# AC7840x register map
Vendor: AutoChips; Series: AC78; File version: 1.0
CPU: CM4 r0p1, little endian, MPU, FPU, VTOR, 4 interrupt priority bits
Registers are 32-bit, read-write, reset 0x0 unless marked. A register's access mark holds for its fields unless they carry their own. Offsets are from the block's base; [hi:lo] are bit positions; {n}, {i} and the like mark numbered series.

## SPI0 — Serial Peripheral Interface
Base 0x4000C000
Same registers: SPI1 0x4000C800, SPI2 0x4000D000
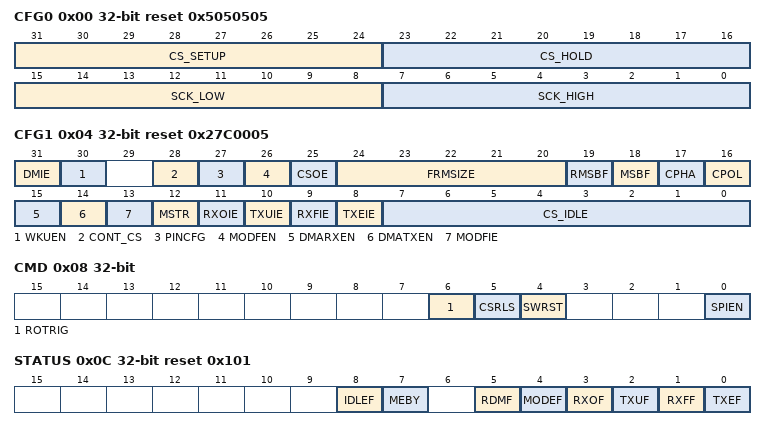
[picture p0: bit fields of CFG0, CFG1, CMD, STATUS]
0x00 CFG0 reset 0x5050505 — SPI Configuration Register 0
  [31:24] CS_SETUP — CS Setup Count
  [23:16] CS_HOLD — CS hold count
  [15:8] SCK_LOW — SCK low count
  [7:0] SCK_HIGH — SCK High Count
0x04 CFG1 reset 0x27C0005 — SPI Configuration Register 1
  [31] DMIE — Data match interrupt enable
    0=Disable; 1=Enable
  [30] WKUEN — wake up function enable(only valid for slave mode)
    0=Disable; 1=Enable
  [28] CONT_CS — CS continuous output enable
    0=Disable; 1=Enable
  [27] PINCFG — SOUT, SIN pin mode configuration
    0=SPI_SOUT_MOSI_SIN_MISO; 1=SPI_SOUT_MISO_SIN_MOSI
  [26] MODFEN — mode fault detect enable
    0=Disable; 1=Enable
  [25] CSOE — CS hardware output enable
    0=Disable; 1=Enable
  [24:20] FRMSIZE — frame size
    {v}=Frame size is 4 bits (v=0..3); {v}=Frame size is {v+1} bits (v=4..31)
  [19] RMSBF — RX MSB first Select
    0=RX LSB first; 1=RX MSB first
  [18] MSBF — TX MSB first Select
    0=TX LSB first; 1=TX MSB first
  [17] CPHA — clock phase
    0=the second SCK transition is the first data capture edge; 1=the first SCK transition is the first data capture edge
  [16] CPOL — clock polarity
    0=SCK is 0 when idle; 1=SCK is 1 when idle
  [15] DMARXEN — DMA RX channel enable
    0=Disable; 1=Enable
  [14] DMATXEN — DMA TX channel enable
    0=Disable; 1=Enable
  [13] MODFIE — mode fault interrupt enable
    0=Disable; 1=Enable
  [12] MSTR — master/slave mode selection
    0=SLAVE (SPI slave mode); 1=MASTER (SPI master mode)
  [11] RXOIE — RX buffer overflow interrupt enable
    0=Disable; 1=Enable
  [10] TXUIE — TX buffer underflow interrupt enable
    0=Disable; 1=Enable
  [9] RXFIE — RX buffer full interrupt enable
    0=Disable; 1=Enable
  [8] TXEIE — TX buffer empty interrupt enable
    0=Disable; 1=Enable
  [7:0] CS_IDLE — CS idle time
0x08 CMD — SPI Command Register
  [6] ROTRIG — Master RX only mode trigger
    0=No effect; 1=Trigger read
  [5] CSRLS — CS release(only valid for CS continuous output)
    0=No effect; 1=Release CS
  [4] SWRST — software reset
    0=No effect; 1=Reset
  [0] SPIEN — SPI Enable
    0=Disable; 1=Enable
0x0C STATUS reset 0x101 — SPI Status Register
  [8] IDLEF — SPI module hardware idle flag
    0=Not idle; 1=Idle
  [7] MEBY — SPI master engine busy flag
    0=Transmission finished; 1=Transmission not finish
  [5] RDMF — Receive data match flag
    0=No RX data match; 1=RX data match
  [4] MODEF — Mode error flag
    0=No mode fault; 1=Mode fault
  [3] RXOF — RX buffer overflow flag
    0=No RX overflow; 1=RX overflow
  [2] TXUF — TX buffer underflow flag
    0=No TX underflow; 1=TX underflow
  [1] RXFF — RX buffer Full flag
    0=RX not full; 1=RX full
  [0] TXEF — TX buffer empty flag
    0=TX Not empty; 1=TX empty
0x10 DATA — SPI Data Register
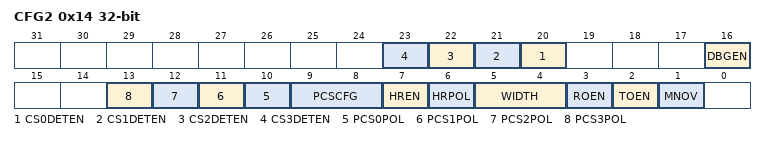
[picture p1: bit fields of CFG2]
0x14 CFG2 reset not defined — SPI configuration register 2
  [n+20] CS{n}DETEN (n=0..3) — CS{n} master mode fault detect enable
    0=disable; 1=enable
  [16] DBGEN — Debug Enable
    0=SPI disable in debug mode; 1=SPI enable in debug mode
  [n+10] PCS{n}POL (n=0..3) — Peripheral Chip Select{n} Polarity
    0=Active low; 1=Active high
  [9:8] PCSCFG — Peripheral Chip Select Configuration
    {v}=PCS{v} enable (v=0..3)
  [7] HREN — HREQ enable
    0=Disable; 1=Enable
  [6] HRPOL — HREQ polarity
    0=Active low; 1=Active high
  [5:4] WIDTH — Transfer width
    0=1 bit; 1=2 bits; 2=4 bits
  [3] ROEN — RX only mode enable bit
    0=Disable; 1=Enable
  [2] TOEN — TX only mode enable bit
    0=Disable; 1=Enable
  [1] MNOV — Master No Overflow mode enable bit
    0=Disable; 1=Enable
0x20 DMV reset not defined — SPI data match register
  [31:0] DMV — SPI data match value
